AUTOSAR XML (schema 4-2-2)
package /ASW_COM_STD_Package
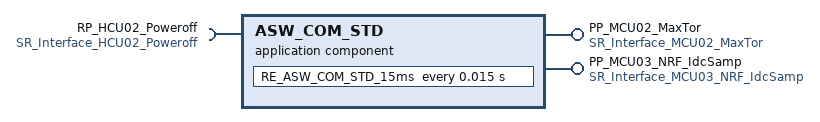
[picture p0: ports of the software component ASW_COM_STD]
  application sw component type ASW_COM_STD
    require port RP_HCU02_Poweroff: nonqueued-receiver-com-spec{data-element=DE_HCU02_Poweroff, alive-timeout=0.3}, required-interface=SR_Interface_HCU02_Poweroff
    provide port PP_MCU02_MaxTor: nonqueued-sender-com-spec=DE_MCU02_MaxTor, provided-interface=SR_Interface_MCU02_MaxTor
    provide port PP_MCU03_NRF_IdcSamp: nonqueued-sender-com-spec=DE_MCU03_NRF_IdcSamp, provided-interface=SR_Interface_MCU03_NRF_IdcSamp
    behavior IB_ASW_COM_STD
      timing event TE_15ms: start-on-event=RE_ASW_COM_STD_15ms, period=0.015
      data receive error event DREE_RP_HCU02_Poweroff_Timeout: start-on-event=RE_ASW_COM_STD_15ms, data=RP_HCU02_Poweroff.DE_HCU02_Poweroff
      runnable RE_ASW_COM_STD_15ms
        data-read-accesses:
          data read access DRA_HCU02_Poweroff: accessed-variable=RP_HCU02_Poweroff.DE_HCU02_Poweroff
        data-write-accesses:
          data write access DWA_MCU02_MaxTor: accessed-variable=PP_MCU02_MaxTor.DE_MCU02_MaxTor
          data write access DWA_MCU03_NRF_IdcSamp: accessed-variable=PP_MCU03_NRF_IdcSamp.DE_MCU03_NRF_IdcSamp
